AUTOSAR XML (schema 314)
package /ComponentType
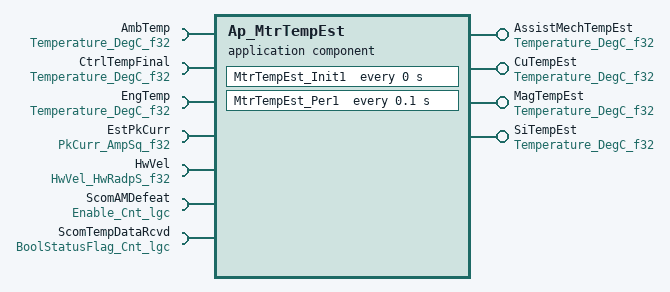
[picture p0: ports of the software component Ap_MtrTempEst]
  application software component type Ap_MtrTempEst
    4 x provide port, all with unqueued-sender-com-spec{data-element=DegC_f32, can-invalidate=false, init-value=D_ZERO_ULS_F32}, provided-interface=Temperature_DegC_f32:
      AssistMechTempEst
      CuTempEst
      MagTempEst
      SiTempEst
    7 x require port:
      AmbTemp: unqueued-receiver-com-spec{data-element=DegC_f32, init-value=D_ZERO_ULS_F32}, required-interface=Temperature_DegC_f32
      CtrlTempFinal: unqueued-receiver-com-spec{data-element=DegC_f32, init-value=D_ZERO_ULS_F32}, required-interface=Temperature_DegC_f32
      EngTemp: unqueued-receiver-com-spec{data-element=DegC_f32, init-value=D_ZERO_ULS_F32}, required-interface=Temperature_DegC_f32
      EstPkCurr: unqueued-receiver-com-spec{data-element=AmpSq_f32, init-value=D_ZERO_ULS_F32}, required-interface=PkCurr_AmpSq_f32
      HwVel: unqueued-receiver-com-spec{data-element=HwRadpS_f32, init-value=D_ZERO_ULS_F32}, required-interface=HwVel_HwRadpS_f32
      ScomAMDefeat: unqueued-receiver-com-spec{data-element=Cnt_lgc, init-value=D_FALSE_CNT_LGC}, required-interface=Enable_Cnt_lgc
      ScomTempDataRcvd: unqueued-receiver-com-spec{data-element=Cnt_lgc, init-value=D_FALSE_CNT_LGC}, required-interface=BoolStatusFlag_Cnt_lgc
  internal behavior Ap_MtrTempEst_InternalBehavior: component=Ap_MtrTempEst
    timing event MtrTempEst_Init1_InitEvent: start-on-event=MtrTempEst_Init1, period=0
    timing event TMT_MtrTempEst_Per1: start-on-event=MtrTempEst_Per1, period=0.1
    port-api-options:
      enable-take-address=false, indirect-api=false, port=AmbTemp
      enable-take-address=false, indirect-api=false, port=AssistMechTempEst
      enable-take-address=false, indirect-api=false, port=CtrlTempFinal
      enable-take-address=false, indirect-api=false, port=CuTempEst
      enable-take-address=false, indirect-api=false, port=EngTemp
      enable-take-address=false, indirect-api=false, port=EstPkCurr
      enable-take-address=false, indirect-api=false, port=HwVel
      enable-take-address=false, indirect-api=false, port=MagTempEst
      enable-take-address=false, indirect-api=false, port=ScomAMDefeat
      enable-take-address=false, indirect-api=false, port=ScomTempDataRcvd
      enable-take-address=false, indirect-api=false, port=SiTempEst
    runnable MtrTempEst_Init1
      4 x data read access:
        READ_AmbTemp_DegC_f32: data-element=AmbTemp.DegC_f32
        READ_CtrlTempFinal_DegC_f32: data-element=CtrlTempFinal.DegC_f32
        READ_EngTemp_DegC_f32: data-element=EngTemp.DegC_f32
        READ_ScomTempDataRcvd_Cnt_lgc: data-element=ScomTempDataRcvd.Cnt_lgc
      4 x data write access:
        WRITE_AssistMechTempEst_DegC_f32: data-element=AssistMechTempEst.DegC_f32
        WRITE_CuTempEst_DegC_f32: data-element=CuTempEst.DegC_f32
        WRITE_MagTempEst_DegC_f32: data-element=MagTempEst.DegC_f32
        WRITE_SiTempEst_DegC_f32: data-element=SiTempEst.DegC_f32
    runnable MtrTempEst_Per1
      7 x data read access:
        READ_AmbTemp_DegC_f32: data-element=AmbTemp.DegC_f32
        READ_CtrlTempFinal_DegC_f32: data-element=CtrlTempFinal.DegC_f32
        READ_EngTemp_DegC_f32: data-element=EngTemp.DegC_f32
        READ_EstPkCurr_AmpSq_f32: data-element=EstPkCurr.AmpSq_f32
        READ_HwVel_HwRadpS_f32: data-element=HwVel.HwRadpS_f32
        READ_ScomAMDefeat_Cnt_lgc: data-element=ScomAMDefeat.Cnt_lgc
        READ_ScomTempDataRcvd_Cnt_lgc: data-element=ScomTempDataRcvd.Cnt_lgc
      4 x data write access:
        WRITE_AssistMechTempEst_DegC_f32: data-element=AssistMechTempEst.DegC_f32
        WRITE_CuTempEst_DegC_f32: data-element=CuTempEst.DegC_f32
        WRITE_MagTempEst_DegC_f32: data-element=MagTempEst.DegC_f32
        WRITE_SiTempEst_DegC_f32: data-element=SiTempEst.DegC_f32
  swc implementation Ap_MtrTempEst_Implementation: behavior=Ap_MtrTempEst_InternalBehavior
    code-descriptors:
      code Code: type=SRC
